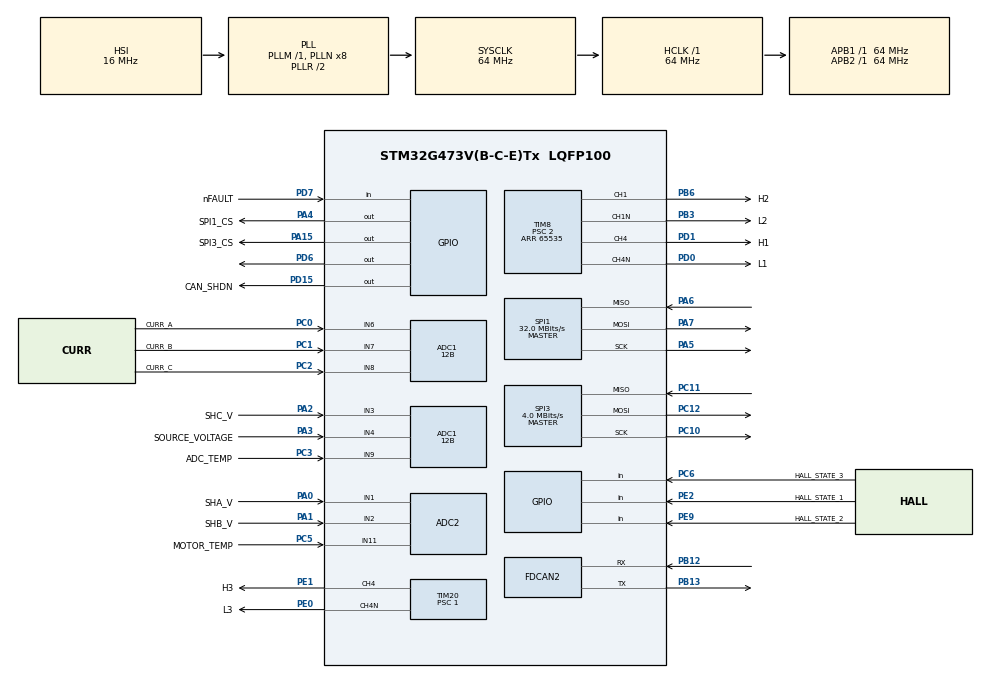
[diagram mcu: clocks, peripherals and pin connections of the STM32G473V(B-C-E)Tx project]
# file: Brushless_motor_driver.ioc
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ADC1.Channel-1\#ChannelRegularConversion=ADC_CHANNEL_6
ADC1.Channel-2\#ChannelRegularConversion=ADC_CHANNEL_7
ADC1.Channel-3\#ChannelRegularConversion=ADC_CHANNEL_8
ADC1.ContinuousConvMode=ENABLE
ADC1.EOCSelection=ADC_EOC_SEQ_CONV
ADC1.NbrOfConversion=3
ADC1.NbrOfConversionFlag=1
ADC1.OffsetNumber-2\#ChannelRegularConversion=ADC_OFFSET_NONE
ADC1.OffsetNumber-3\#ChannelRegularConversion=ADC_OFFSET_NONE
ADC1.Rank-2\#ChannelRegularConversion=2
ADC1.Rank-3\#ChannelRegularConversion=3
ADC1.Resolution=ADC_RESOLUTION_12B
ADC1.SamplingTime-1\#ChannelRegularConversion=ADC_SAMPLETIME_12CYCLES_5
ADC1.SamplingTime-2\#ChannelRegularConversion=ADC_SAMPLETIME_12CYCLES_5
ADC1.SamplingTime-3\#ChannelRegularConversion=ADC_SAMPLETIME_12CYCLES_5
ADC1.master=1
ADC2.Channel-1\#ChannelRegularConversion=ADC_CHANNEL_11
ADC2.NbrOfConversionFlag=1
ADC2.OffsetNumber-1\#ChannelRegularConversion=ADC_OFFSET_NONE
ADC2.Rank-1\#ChannelRegularConversion=1
ADC2.SamplingTime-1\#ChannelRegularConversion=ADC_SAMPLETIME_2CYCLES_5
Dma.ADC1.0.Direction=DMA_PERIPH_TO_MEMORY
Dma.ADC1.0.EventEnable=DISABLE
Dma.ADC1.0.Instance=DMA1_Channel1
Dma.ADC1.0.MemDataAlignment=DMA_MDATAALIGN_WORD
Dma.ADC1.0.MemInc=DMA_MINC_ENABLE
Dma.ADC1.0.Mode=DMA_NORMAL
Dma.ADC1.0.PeriphDataAlignment=DMA_PDATAALIGN_WORD
Dma.ADC1.0.PeriphInc=DMA_PINC_DISABLE
Dma.ADC1.0.Polarity=HAL_DMAMUX_REQ_GEN_RISING
Dma.ADC1.0.Priority=DMA_PRIORITY_MEDIUM
Dma.ADC1.0.RequestNumber=1
Dma.ADC1.0.SignalID=NONE
Dma.ADC1.0.SyncEnable=DISABLE
Dma.ADC1.0.SyncPolarity=HAL_DMAMUX_SYNC_NO_EVENT
Dma.ADC1.0.SyncRequestNumber=1
Dma.ADC1.0.SyncSignalID=NONE
Dma.Request0=ADC1
FDCAN2.CalculateBaudRateNominal=800000
FDCAN2.CalculateTimeBitNominal=1250
FDCAN2.CalculateTimeQuantumNominal=250.0
Mcu.Family=STM32G4
Mcu.Name=STM32G473V(B-C-E)Tx
Mcu.Package=LQFP100
NVIC.CORDIC_IRQn=true\:0\:0\:false\:false\:true\:true\:true\:true
NVIC.DMA1_Channel1_IRQn=true\:0\:0\:false\:false\:true\:false\:true\:true
NVIC.PriorityGroup=NVIC_PRIORITYGROUP_4
NVIC.TIM2_IRQn=true\:0\:0\:false\:false\:true\:true\:true\:true
NVIC.TIM3_IRQn=true\:0\:0\:false\:false\:true\:true\:true\:true
PA0.GPIO_Label=SHA_V
PA0.GPIO_Mode=GPIO_MODE_ANALOG
PA0.GPIO_PuPd=GPIO_NOPULL
PA0.Mode=IN1-Single-Ended
PA0.Signal=ADC2_IN1
PA1.GPIO_Label=SHB_V
PA1.GPIO_Mode=GPIO_MODE_ANALOG
PA1.GPIO_PuPd=GPIO_NOPULL
PA1.Mode=IN2-Single-Ended
PA1.Signal=ADC2_IN2
PA13.Mode=Serial_Wire
PA13.Signal=SYS_JTMS-SWDIO
PA14.Mode=Serial_Wire
PA14.Signal=SYS_JTCK-SWCLK
PA15.GPIO_Label=SPI3_CS
PA15.Signal=GPIO_Output
PA2.GPIO_Label=SHC_V
PA2.GPIO_Mode=GPIO_MODE_ANALOG
PA2.GPIO_PuPd=GPIO_NOPULL
PA2.Mode=IN3-Single-Ended
PA2.Signal=ADC1_IN3
PA3.GPIO_Label=SOURCE_VOLTAGE
PA3.GPIO_Mode=GPIO_MODE_ANALOG
PA3.GPIO_PuPd=GPIO_NOPULL
PA3.Mode=IN4-Single-Ended
PA3.Signal=ADC1_IN4
PA4.GPIO_Label=SPI1_CS
PA4.Signal=GPIO_Output
PA5.Mode=Full_Duplex_Master
PA5.Signal=SPI1_SCK
PA6.Mode=Full_Duplex_Master
PA6.Signal=SPI1_MISO
PA7.Mode=Full_Duplex_Master
PA7.Signal=SPI1_MOSI
PB12.Mode=FDCAN_Activate
PB12.Signal=FDCAN2_RX
PB13.Mode=FDCAN_Activate
PB13.Signal=FDCAN2_TX
PB3.GPIO_Label=L2
PB3.Mode=PWM Generation1 CH1 CH1N
PB3.Signal=TIM8_CH1N
PB6.GPIO_Label=H2
PB6.Signal=S_TIM8_CH1
PC0.GPIO_Label=CURR_A
PC0.GPIO_Mode=GPIO_MODE_ANALOG
PC0.GPIO_PuPd=GPIO_NOPULL
PC0.Mode=IN6-Single-Ended
PC0.Signal=ADC1_IN6
PC1.GPIO_Label=CURR_B
PC1.GPIO_Mode=GPIO_MODE_ANALOG
PC1.GPIO_PuPd=GPIO_NOPULL
PC1.Mode=IN7-Single-Ended
PC1.Signal=ADC1_IN7
PC10.Mode=Full_Duplex_Master
PC10.Signal=SPI3_SCK
PC11.Mode=Full_Duplex_Master
PC11.Signal=SPI3_MISO
PC12.Mode=Full_Duplex_Master
PC12.Signal=SPI3_MOSI
PC2.GPIO_Label=CURR_C
PC2.GPIO_Mode=GPIO_MODE_ANALOG
PC2.GPIO_PuPd=GPIO_NOPULL
PC2.Mode=IN8-Single-Ended
PC2.Signal=ADC1_IN8
PC3.GPIO_Label=ADC_TEMP
PC3.GPIO_Mode=GPIO_MODE_ANALOG
PC3.GPIO_PuPd=GPIO_NOPULL
PC3.Mode=IN9-Single-Ended
PC3.Signal=ADC1_IN9
PC5.GPIO_Label=MOTOR_TEMP
PC5.Mode=IN11-Single-Ended
PC5.Signal=ADC2_IN11
PC6.GPIO_Label=HALL_STATE_3
PC6.Signal=GPIO_Input
PD0.GPIO_Label=L1
PD0.Mode=PWM Generation4 CH4 CH4N
PD0.Signal=TIM8_CH4N
PD1.GPIO_Label=H1
PD1.Signal=S_TIM8_CH4
PD15.GPIO_Label=CAN_SHDN
PD15.Signal=GPIO_Output
PD6.Signal=GPIO_Output
PD7.GPIO_Label=nFAULT
PD7.Signal=GPIO_Input
PE0.GPIO_Label=L3
PE0.Mode=PWM Generation4 CH4 CH4N
PE0.Signal=TIM20_CH4N
PE1.GPIO_Label=H3
PE1.Signal=S_TIM20_CH4
PE2.GPIO_Label=HALL_STATE_1
PE2.Signal=GPIO_Input
PE9.GPIO_Label=HALL_STATE_2
PE9.Signal=GPIO_Input
ProjectManager.HeapSize=0x200
ProjectManager.StackSize=0x400
ProjectManager.TargetToolchain=STM32CubeIDE
RCC.ADC12Freq_Value=64000000
RCC.ADC345Freq_Value=64000000
RCC.AHBFreq_Value=64000000
RCC.APB1Freq_Value=64000000
RCC.APB1TimFreq_Value=64000000
RCC.APB2Freq_Value=64000000
RCC.APB2TimFreq_Value=64000000
RCC.CortexFreq_Value=64000000
RCC.EXTERNAL_CLOCK_VALUE=12288000
RCC.HCLKFreq_Value=64000000
RCC.HSE_VALUE=8000000
RCC.HSI48_VALUE=48000000
RCC.HSI_VALUE=16000000
RCC.LSE_VALUE=32768
RCC.SYSCLKFreq_VALUE=64000000
RCC.SYSCLKSource=RCC_SYSCLKSOURCE_PLLCLK
RCC.USBFreq_Value=64000000
RCC.VCOOutputFreq_Value=128000000
SH.S_TIM20_CH4.0=TIM20_CH4,PWM Generation4 CH4 CH4N
SH.S_TIM8_CH1.0=TIM8_CH1,PWM Generation1 CH1 CH1N
SH.S_TIM8_CH4.0=TIM8_CH4,PWM Generation4 CH4 CH4N
SPI1.BaudRatePrescaler=SPI_BAUDRATEPRESCALER_2
SPI1.CalculateBaudRate=32.0 MBits/s
SPI1.Direction=SPI_DIRECTION_2LINES
SPI1.Mode=SPI_MODE_MASTER
SPI1.VirtualType=VM_MASTER
SPI3.BaudRatePrescaler=SPI_BAUDRATEPRESCALER_16
SPI3.CalculateBaudRate=4.0 MBits/s
SPI3.Direction=SPI_DIRECTION_2LINES
SPI3.Mode=SPI_MODE_MASTER
SPI3.VirtualType=VM_MASTER
TIM2.Channel-Output\ Compare1\ No\ Output=TIM_CHANNEL_1
TIM2.PeriodNoDither=71582788
TIM20.Channel-PWM\ Generation4\ CH4\ CH4N=TIM_CHANNEL_4
TIM20.CounterMode=TIM_COUNTERMODE_CENTERALIGNED2
TIM20.OCMode_PWM-PWM\ Generation4\ CH4\ CH4N=TIM_OCMODE_PWM1
TIM20.PeriodNoDither=65535
TIM20.Prescaler=1
TIM8.AutoReloadPreload=TIM_AUTORELOAD_PRELOAD_ENABLE
TIM8.Channel-PWM\ Generation1\ CH1\ CH1N=TIM_CHANNEL_1
TIM8.Channel-PWM\ Generation4\ CH4\ CH4N=TIM_CHANNEL_4
TIM8.CounterMode=TIM_COUNTERMODE_CENTERALIGNED2
TIM8.OCMode_PWM-PWM\ Generation4\ CH4\ CH4N=TIM_OCMODE_PWM1
TIM8.PeriodNoDither=65535
TIM8.Prescaler=2
VP_CORDIC_VS_CORDIC.Mode=CORDIC_Activate
VP_SYS_VS_DBSignals.Mode=DisableDeadBatterySignals
VP_TIM1_VS_ClockSourceINT.Mode=Internal
VP_TIM20_VS_ClockSourceINT.Mode=Internal
VP_TIM2_VS_ClockSourceINT.Mode=Internal
VP_TIM2_VS_no_output1.Mode=Output Compare1 No Output
VP_TIM3_VS_ClockSourceINT.Mode=Internal
VP_TIM8_VS_ClockSourceINT.Mode=Internal
board=custom

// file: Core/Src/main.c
/* USER CODE BEGIN Header */
/**
  ******************************************************************************
  * @file           : main.c
  * @brief          : Main program body
  ******************************************************************************
  * @attention
  *
  * Copyright (c) 2023 STMicroelectronics.
  * All rights reserved.
  *
  * This software is licensed under terms that can be found in the LICENSE file
  * in the root directory of this software component.
  * If no LICENSE file comes with this software, it is provided AS-IS.
  *
  ******************************************************************************
  */
/* USER CODE END Header */
#include "main.h"

/* USER CODE BEGIN Includes */
#include "main_bridge.h"
/* USER CODE END Includes */

ADC_HandleTypeDef hadc1;
ADC_HandleTypeDef hadc2;
DMA_HandleTypeDef hdma_adc1;

CORDIC_HandleTypeDef hcordic;

FDCAN_HandleTypeDef hfdcan2;

SPI_HandleTypeDef hspi1;
SPI_HandleTypeDef hspi3;

TIM_HandleTypeDef htim1;
TIM_HandleTypeDef htim2;
TIM_HandleTypeDef htim3;
TIM_HandleTypeDef htim8;
TIM_HandleTypeDef htim20;

void SystemClock_Config(void);
static void MX_GPIO_Init(void);
static void MX_DMA_Init(void);
static void MX_ADC1_Init(void);
static void MX_TIM3_Init(void);
static void MX_ADC2_Init(void);
static void MX_TIM2_Init(void);
static void MX_TIM1_Init(void);
static void MX_TIM8_Init(void);
static void MX_TIM20_Init(void);
static void MX_FDCAN2_Init(void);
static void MX_SPI1_Init(void);
static void MX_SPI3_Init(void);
static void MX_CORDIC_Init(void);

int main(void)
{
  /* USER CODE BEGIN 1 */
	TIM2->CCR1 = 17895697;
  /* USER CODE END 1 */

  /* MCU Configuration--------------------------------------------------------*/

  /* Reset of all peripherals, Initializes the Flash interface and the Systick. */
  HAL_Init();

  /* Configure the system clock */
  SystemClock_Config();

  /* Initialize all configured peripherals */
  MX_GPIO_Init();
  MX_DMA_Init();
  MX_ADC1_Init();
  MX_TIM3_Init();
  MX_ADC2_Init();
  MX_TIM2_Init();
  MX_TIM1_Init();
  MX_TIM8_Init();
  MX_TIM20_Init();
  MX_FDCAN2_Init();
  MX_SPI1_Init();
  MX_SPI3_Init();
  MX_CORDIC_Init();
  /* USER CODE BEGIN 2 */
  setup();
  /* USER CODE END 2 */

  /* Infinite loop */
  /* USER CODE BEGIN WHILE */
  while (1)
  {
	  loop();
    /* USER CODE END WHILE */

  }
}

void SystemClock_Config(void)
{
  RCC_OscInitTypeDef RCC_OscInitStruct = {0};
  RCC_ClkInitTypeDef RCC_ClkInitStruct = {0};

  /** Configure the main internal regulator output voltage
  */
  HAL_PWREx_ControlVoltageScaling(PWR_REGULATOR_VOLTAGE_SCALE1);

  /** Initializes the RCC Oscillators according to the specified parameters
  * in the RCC_OscInitTypeDef structure.
  */
  RCC_OscInitStruct.OscillatorType = RCC_OSCILLATORTYPE_HSI;
  RCC_OscInitStruct.HSIState = RCC_HSI_ON;
  RCC_OscInitStruct.HSICalibrationValue = RCC_HSICALIBRATION_DEFAULT;
  RCC_OscInitStruct.PLL.PLLState = RCC_PLL_ON;
  RCC_OscInitStruct.PLL.PLLSource = RCC_PLLSOURCE_HSI;
  RCC_OscInitStruct.PLL.PLLM = RCC_PLLM_DIV1;
  RCC_OscInitStruct.PLL.PLLN = 8;
  RCC_OscInitStruct.PLL.PLLP = RCC_PLLP_DIV2;
  RCC_OscInitStruct.PLL.PLLQ = RCC_PLLQ_DIV2;
  RCC_OscInitStruct.PLL.PLLR = RCC_PLLR_DIV2;
  if (HAL_RCC_OscConfig(&RCC_OscInitStruct) != HAL_OK)
  {
    Error_Handler();
  }

  /** Initializes the CPU, AHB and APB buses clocks
  */
  RCC_ClkInitStruct.ClockType = RCC_CLOCKTYPE_HCLK|RCC_CLOCKTYPE_SYSCLK
                              |RCC_CLOCKTYPE_PCLK1|RCC_CLOCKTYPE_PCLK2;
  RCC_ClkInitStruct.SYSCLKSource = RCC_SYSCLKSOURCE_PLLCLK;
  RCC_ClkInitStruct.AHBCLKDivider = RCC_SYSCLK_DIV1;
  RCC_ClkInitStruct.APB1CLKDivider = RCC_HCLK_DIV1;
  RCC_ClkInitStruct.APB2CLKDivider = RCC_HCLK_DIV1;

  if (HAL_RCC_ClockConfig(&RCC_ClkInitStruct, FLASH_LATENCY_2) != HAL_OK)
  {
    Error_Handler();
  }
}

static void MX_ADC1_Init(void)
{

  ADC_MultiModeTypeDef multimode = {0};
  ADC_ChannelConfTypeDef sConfig = {0};

  /** Common config
  */
  hadc1.Instance = ADC1;
  hadc1.Init.ClockPrescaler = ADC_CLOCK_SYNC_PCLK_DIV2;
  hadc1.Init.Resolution = ADC_RESOLUTION_12B;
  hadc1.Init.DataAlign = ADC_DATAALIGN_RIGHT;
  hadc1.Init.GainCompensation = 0;
  hadc1.Init.ScanConvMode = ADC_SCAN_ENABLE;
  hadc1.Init.EOCSelection = ADC_EOC_SEQ_CONV;
  hadc1.Init.LowPowerAutoWait = DISABLE;
  hadc1.Init.ContinuousConvMode = ENABLE;
  hadc1.Init.NbrOfConversion = 3;
  hadc1.Init.DiscontinuousConvMode = DISABLE;
  hadc1.Init.ExternalTrigConv = ADC_SOFTWARE_START;
  hadc1.Init.ExternalTrigConvEdge = ADC_EXTERNALTRIGCONVEDGE_NONE;
  hadc1.Init.DMAContinuousRequests = DISABLE;
  hadc1.Init.Overrun = ADC_OVR_DATA_PRESERVED;
  hadc1.Init.OversamplingMode = DISABLE;
  if (HAL_ADC_Init(&hadc1) != HAL_OK)
  {
    Error_Handler();
  }

  /** Configure the ADC multi-mode
  */
  multimode.Mode = ADC_MODE_INDEPENDENT;
  if (HAL_ADCEx_MultiModeConfigChannel(&hadc1, &multimode) != HAL_OK)
  {
    Error_Handler();
  }

  /** Configure Regular Channel
  */
  sConfig.Channel = ADC_CHANNEL_6;
  sConfig.Rank = ADC_REGULAR_RANK_1;
  sConfig.SamplingTime = ADC_SAMPLETIME_12CYCLES_5;
  sConfig.SingleDiff = ADC_SINGLE_ENDED;
  sConfig.OffsetNumber = ADC_OFFSET_NONE;
  sConfig.Offset = 0;
  if (HAL_ADC_ConfigChannel(&hadc1, &sConfig) != HAL_OK)
  {
    Error_Handler();
  }

  /** Configure Regular Channel
  */
  sConfig.Channel = ADC_CHANNEL_7;
  sConfig.Rank = ADC_REGULAR_RANK_2;
  if (HAL_ADC_ConfigChannel(&hadc1, &sConfig) != HAL_OK)
  {
    Error_Handler();
  }

  /** Configure Regular Channel
  */
  sConfig.Channel = ADC_CHANNEL_8;
  sConfig.Rank = ADC_REGULAR_RANK_3;
  if (HAL_ADC_ConfigChannel(&hadc1, &sConfig) != HAL_OK)
  {
    Error_Handler();
  }

}

static void MX_ADC2_Init(void)
{

  ADC_ChannelConfTypeDef sConfig = {0};

  /** Common config
  */
  hadc2.Instance = ADC2;
  hadc2.Init.ClockPrescaler = ADC_CLOCK_SYNC_PCLK_DIV2;
  hadc2.Init.Resolution = ADC_RESOLUTION_12B;
  hadc2.Init.DataAlign = ADC_DATAALIGN_RIGHT;
  hadc2.Init.GainCompensation = 0;
  hadc2.Init.ScanConvMode = ADC_SCAN_DISABLE;
  hadc2.Init.EOCSelection = ADC_EOC_SINGLE_CONV;
  hadc2.Init.LowPowerAutoWait = DISABLE;
  hadc2.Init.ContinuousConvMode = DISABLE;
  hadc2.Init.NbrOfConversion = 1;
  hadc2.Init.DiscontinuousConvMode = DISABLE;
  hadc2.Init.ExternalTrigConv = ADC_SOFTWARE_START;
  hadc2.Init.ExternalTrigConvEdge = ADC_EXTERNALTRIGCONVEDGE_NONE;
  hadc2.Init.DMAContinuousRequests = DISABLE;
  hadc2.Init.Overrun = ADC_OVR_DATA_PRESERVED;
  hadc2.Init.OversamplingMode = DISABLE;
  if (HAL_ADC_Init(&hadc2) != HAL_OK)
  {
    Error_Handler();
  }

  /** Configure Regular Channel
  */
  sConfig.Channel = ADC_CHANNEL_11;
  sConfig.Rank = ADC_REGULAR_RANK_1;
  sConfig.SamplingTime = ADC_SAMPLETIME_2CYCLES_5;
  sConfig.SingleDiff = ADC_SINGLE_ENDED;
  sConfig.OffsetNumber = ADC_OFFSET_NONE;
  sConfig.Offset = 0;
  if (HAL_ADC_ConfigChannel(&hadc2, &sConfig) != HAL_OK)
  {
    Error_Handler();
  }

}

static void MX_CORDIC_Init(void)
{

  hcordic.Instance = CORDIC;
  if (HAL_CORDIC_Init(&hcordic) != HAL_OK)
  {
    Error_Handler();
  }

}

static void MX_FDCAN2_Init(void)
{

  hfdcan2.Instance = FDCAN2;
  hfdcan2.Init.ClockDivider = FDCAN_CLOCK_DIV1;
  hfdcan2.Init.FrameFormat = FDCAN_FRAME_CLASSIC;
  hfdcan2.Init.Mode = FDCAN_MODE_NORMAL;
  hfdcan2.Init.AutoRetransmission = DISABLE;
  hfdcan2.Init.TransmitPause = DISABLE;
  hfdcan2.Init.ProtocolException = DISABLE;
  hfdcan2.Init.NominalPrescaler = 16;
  hfdcan2.Init.NominalSyncJumpWidth = 1;
  hfdcan2.Init.NominalTimeSeg1 = 2;
  hfdcan2.Init.NominalTimeSeg2 = 2;
  hfdcan2.Init.DataPrescaler = 1;
  hfdcan2.Init.DataSyncJumpWidth = 1;
  hfdcan2.Init.DataTimeSeg1 = 1;
  hfdcan2.Init.DataTimeSeg2 = 1;
  hfdcan2.Init.StdFiltersNbr = 0;
  hfdcan2.Init.ExtFiltersNbr = 0;
  hfdcan2.Init.TxFifoQueueMode = FDCAN_TX_FIFO_OPERATION;
  if (HAL_FDCAN_Init(&hfdcan2) != HAL_OK)
  {
    Error_Handler();
  }

}

static void MX_SPI1_Init(void)
{

  /* SPI1 parameter configuration*/
  hspi1.Instance = SPI1;
  hspi1.Init.Mode = SPI_MODE_MASTER;
  hspi1.Init.Direction = SPI_DIRECTION_2LINES;
  hspi1.Init.DataSize = SPI_DATASIZE_4BIT;
  hspi1.Init.CLKPolarity = SPI_POLARITY_LOW;
  hspi1.Init.CLKPhase = SPI_PHASE_1EDGE;
  hspi1.Init.NSS = SPI_NSS_SOFT;
  hspi1.Init.BaudRatePrescaler = SPI_BAUDRATEPRESCALER_2;
  hspi1.Init.FirstBit = SPI_FIRSTBIT_MSB;
  hspi1.Init.TIMode = SPI_TIMODE_DISABLE;
  hspi1.Init.CRCCalculation = SPI_CRCCALCULATION_DISABLE;
  hspi1.Init.CRCPolynomial = 7;
  hspi1.Init.CRCLength = SPI_CRC_LENGTH_DATASIZE;
  hspi1.Init.NSSPMode = SPI_NSS_PULSE_ENABLE;
  if (HAL_SPI_Init(&hspi1) != HAL_OK)
  {
    Error_Handler();
  }

}

static void MX_SPI3_Init(void)
{

  /* SPI3 parameter configuration*/
  hspi3.Instance = SPI3;
  hspi3.Init.Mode = SPI_MODE_MASTER;
  hspi3.Init.Direction = SPI_DIRECTION_2LINES;
  hspi3.Init.DataSize = SPI_DATASIZE_4BIT;
  hspi3.Init.CLKPolarity = SPI_POLARITY_LOW;
  hspi3.Init.CLKPhase = SPI_PHASE_1EDGE;
  hspi3.Init.NSS = SPI_NSS_SOFT;
  hspi3.Init.BaudRatePrescaler = SPI_BAUDRATEPRESCALER_16;
  hspi3.Init.FirstBit = SPI_FIRSTBIT_MSB;
  hspi3.Init.TIMode = SPI_TIMODE_DISABLE;
  hspi3.Init.CRCCalculation = SPI_CRCCALCULATION_DISABLE;
  hspi3.Init.CRCPolynomial = 7;
  hspi3.Init.CRCLength = SPI_CRC_LENGTH_DATASIZE;
  hspi3.Init.NSSPMode = SPI_NSS_PULSE_ENABLE;
  if (HAL_SPI_Init(&hspi3) != HAL_OK)
  {
    Error_Handler();
  }

}

static void MX_TIM1_Init(void)
{

  TIM_ClockConfigTypeDef sClockSourceConfig = {0};
  TIM_MasterConfigTypeDef sMasterConfig = {0};

  htim1.Instance = TIM1;
  htim1.Init.Prescaler = 0;
  htim1.Init.CounterMode = TIM_COUNTERMODE_UP;
  htim1.Init.Period = 65535;
  htim1.Init.ClockDivision = TIM_CLOCKDIVISION_DIV1;
  htim1.Init.RepetitionCounter = 0;
  htim1.Init.AutoReloadPreload = TIM_AUTORELOAD_PRELOAD_DISABLE;
  if (HAL_TIM_Base_Init(&htim1) != HAL_OK)
  {
    Error_Handler();
  }
  sClockSourceConfig.ClockSource = TIM_CLOCKSOURCE_INTERNAL;
  if (HAL_TIM_ConfigClockSource(&htim1, &sClockSourceConfig) != HAL_OK)
  {
    Error_Handler();
  }
  sMasterConfig.MasterOutputTrigger = TIM_TRGO_RESET;
  sMasterConfig.MasterOutputTrigger2 = TIM_TRGO2_RESET;
  sMasterConfig.MasterSlaveMode = TIM_MASTERSLAVEMODE_DISABLE;
  if (HAL_TIMEx_MasterConfigSynchronization(&htim1, &sMasterConfig) != HAL_OK)
  {
    Error_Handler();
  }

}

static void MX_TIM2_Init(void)
{

  TIM_ClockConfigTypeDef sClockSourceConfig = {0};
  TIM_MasterConfigTypeDef sMasterConfig = {0};
  TIM_OC_InitTypeDef sConfigOC = {0};

  htim2.Instance = TIM2;
  htim2.Init.Prescaler = 0;
  htim2.Init.CounterMode = TIM_COUNTERMODE_UP;
  htim2.Init.Period = 7.1582788E7;
  htim2.Init.ClockDivision = TIM_CLOCKDIVISION_DIV1;
  htim2.Init.AutoReloadPreload = TIM_AUTORELOAD_PRELOAD_DISABLE;
  if (HAL_TIM_Base_Init(&htim2) != HAL_OK)
  {
    Error_Handler();
  }
  sClockSourceConfig.ClockSource = TIM_CLOCKSOURCE_INTERNAL;
  if (HAL_TIM_ConfigClockSource(&htim2, &sClockSourceConfig) != HAL_OK)
  {
    Error_Handler();
  }
  if (HAL_TIM_OC_Init(&htim2) != HAL_OK)
  {
    Error_Handler();
  }
  sMasterConfig.MasterOutputTrigger = TIM_TRGO_RESET;
  sMasterConfig.MasterSlaveMode = TIM_MASTERSLAVEMODE_DISABLE;
  if (HAL_TIMEx_MasterConfigSynchronization(&htim2, &sMasterConfig) != HAL_OK)
  {
    Error_Handler();
  }
  sConfigOC.OCMode = TIM_OCMODE_TIMING;
  sConfigOC.Pulse = 0;
  sConfigOC.OCPolarity = TIM_OCPOLARITY_HIGH;
  sConfigOC.OCFastMode = TIM_OCFAST_DISABLE;
  if (HAL_TIM_OC_ConfigChannel(&htim2, &sConfigOC, TIM_CHANNEL_1) != HAL_OK)
  {
    Error_Handler();
  }

}

static void MX_TIM3_Init(void)
{

  TIM_ClockConfigTypeDef sClockSourceConfig = {0};
  TIM_MasterConfigTypeDef sMasterConfig = {0};

  htim3.Instance = TIM3;
  htim3.Init.Prescaler = 0;
  htim3.Init.CounterMode = TIM_COUNTERMODE_UP;
  htim3.Init.Period = 65535;
  htim3.Init.ClockDivision = TIM_CLOCKDIVISION_DIV1;
  htim3.Init.AutoReloadPreload = TIM_AUTORELOAD_PRELOAD_DISABLE;
  if (HAL_TIM_Base_Init(&htim3) != HAL_OK)
  {
    Error_Handler();
  }
  sClockSourceConfig.ClockSource = TIM_CLOCKSOURCE_INTERNAL;
  if (HAL_TIM_ConfigClockSource(&htim3, &sClockSourceConfig) != HAL_OK)
  {
    Error_Handler();
  }
  sMasterConfig.MasterOutputTrigger = TIM_TRGO_RESET;
  sMasterConfig.MasterSlaveMode = TIM_MASTERSLAVEMODE_DISABLE;
  if (HAL_TIMEx_MasterConfigSynchronization(&htim3, &sMasterConfig) != HAL_OK)
  {
    Error_Handler();
  }

}

static void MX_TIM8_Init(void)
{

  TIM_ClockConfigTypeDef sClockSourceConfig = {0};
  TIM_MasterConfigTypeDef sMasterConfig = {0};
  TIM_OC_InitTypeDef sConfigOC = {0};
  TIM_BreakDeadTimeConfigTypeDef sBreakDeadTimeConfig = {0};

  htim8.Instance = TIM8;
  htim8.Init.Prescaler = 2;
  htim8.Init.CounterMode = TIM_COUNTERMODE_CENTERALIGNED2;
  htim8.Init.Period = 65535;
  htim8.Init.ClockDivision = TIM_CLOCKDIVISION_DIV1;
  htim8.Init.RepetitionCounter = 0;
  htim8.Init.AutoReloadPreload = TIM_AUTORELOAD_PRELOAD_ENABLE;
  if (HAL_TIM_Base_Init(&htim8) != HAL_OK)
  {
    Error_Handler();
  }
  sClockSourceConfig.ClockSource = TIM_CLOCKSOURCE_INTERNAL;
  if (HAL_TIM_ConfigClockSource(&htim8, &sClockSourceConfig) != HAL_OK)
  {
    Error_Handler();
  }
  if (HAL_TIM_PWM_Init(&htim8) != HAL_OK)
  {
    Error_Handler();
  }
  sMasterConfig.MasterOutputTrigger = TIM_TRGO_RESET;
  sMasterConfig.MasterOutputTrigger2 = TIM_TRGO2_RESET;
  sMasterConfig.MasterSlaveMode = TIM_MASTERSLAVEMODE_DISABLE;
  if (HAL_TIMEx_MasterConfigSynchronization(&htim8, &sMasterConfig) != HAL_OK)
  {
    Error_Handler();
  }
  sConfigOC.OCMode = TIM_OCMODE_PWM1;
  sConfigOC.Pulse = 0;
  sConfigOC.OCPolarity = TIM_OCPOLARITY_HIGH;
  sConfigOC.OCNPolarity = TIM_OCNPOLARITY_HIGH;
  sConfigOC.OCFastMode = TIM_OCFAST_DISABLE;
  sConfigOC.OCIdleState = TIM_OCIDLESTATE_RESET;
  sConfigOC.OCNIdleState = TIM_OCNIDLESTATE_RESET;
  if (HAL_TIM_PWM_ConfigChannel(&htim8, &sConfigOC, TIM_CHANNEL_1) != HAL_OK)
  {
    Error_Handler();
  }
  if (HAL_TIM_PWM_ConfigChannel(&htim8, &sConfigOC, TIM_CHANNEL_4) != HAL_OK)
  {
    Error_Handler();
  }
  sBreakDeadTimeConfig.OffStateRunMode = TIM_OSSR_DISABLE;
  sBreakDeadTimeConfig.OffStateIDLEMode = TIM_OSSI_DISABLE;
  sBreakDeadTimeConfig.LockLevel = TIM_LOCKLEVEL_OFF;
  sBreakDeadTimeConfig.DeadTime = 0;
  sBreakDeadTimeConfig.BreakState = TIM_BREAK_DISABLE;
  sBreakDeadTimeConfig.BreakPolarity = TIM_BREAKPOLARITY_HIGH;
  sBreakDeadTimeConfig.BreakFilter = 0;
  sBreakDeadTimeConfig.BreakAFMode = TIM_BREAK_AFMODE_INPUT;
  sBreakDeadTimeConfig.Break2State = TIM_BREAK2_DISABLE;
  sBreakDeadTimeConfig.Break2Polarity = TIM_BREAK2POLARITY_HIGH;
  sBreakDeadTimeConfig.Break2Filter = 0;
  sBreakDeadTimeConfig.Break2AFMode = TIM_BREAK_AFMODE_INPUT;
  sBreakDeadTimeConfig.AutomaticOutput = TIM_AUTOMATICOUTPUT_DISABLE;
  if (HAL_TIMEx_ConfigBreakDeadTime(&htim8, &sBreakDeadTimeConfig) != HAL_OK)
  {
    Error_Handler();
  }
  HAL_TIM_MspPostInit(&htim8);

}

static void MX_TIM20_Init(void)
{

  TIM_ClockConfigTypeDef sClockSourceConfig = {0};
  TIM_MasterConfigTypeDef sMasterConfig = {0};
  TIM_OC_InitTypeDef sConfigOC = {0};
  TIM_BreakDeadTimeConfigTypeDef sBreakDeadTimeConfig = {0};

  htim20.Instance = TIM20;
  htim20.Init.Prescaler = 1;
  htim20.Init.CounterMode = TIM_COUNTERMODE_CENTERALIGNED2;
  htim20.Init.Period = 65535;
  htim20.Init.ClockDivision = TIM_CLOCKDIVISION_DIV1;
  htim20.Init.RepetitionCounter = 0;
  htim20.Init.AutoReloadPreload = TIM_AUTORELOAD_PRELOAD_DISABLE;
  if (HAL_TIM_Base_Init(&htim20) != HAL_OK)
  {
    Error_Handler();
  }
  sClockSourceConfig.ClockSource = TIM_CLOCKSOURCE_INTERNAL;
  if (HAL_TIM_ConfigClockSource(&htim20, &sClockSourceConfig) != HAL_OK)
  {
    Error_Handler();
  }
  if (HAL_TIM_PWM_Init(&htim20) != HAL_OK)
  {
    Error_Handler();
  }
  sMasterConfig.MasterOutputTrigger = TIM_TRGO_RESET;
  sMasterConfig.MasterOutputTrigger2 = TIM_TRGO2_RESET;
  sMasterConfig.MasterSlaveMode = TIM_MASTERSLAVEMODE_DISABLE;
  if (HAL_TIMEx_MasterConfigSynchronization(&htim20, &sMasterConfig) != HAL_OK)
  {
    Error_Handler();
  }
  sConfigOC.OCMode = TIM_OCMODE_PWM1;
  sConfigOC.Pulse = 0;
  sConfigOC.OCPolarity = TIM_OCPOLARITY_HIGH;
  sConfigOC.OCNPolarity = TIM_OCNPOLARITY_HIGH;
  sConfigOC.OCFastMode = TIM_OCFAST_DISABLE;
  sConfigOC.OCIdleState = TIM_OCIDLESTATE_RESET;
  sConfigOC.OCNIdleState = TIM_OCNIDLESTATE_RESET;
  if (HAL_TIM_PWM_ConfigChannel(&htim20, &sConfigOC, TIM_CHANNEL_4) != HAL_OK)
  {
    Error_Handler();
  }
  sBreakDeadTimeConfig.OffStateRunMode = TIM_OSSR_DISABLE;
  sBreakDeadTimeConfig.OffStateIDLEMode = TIM_OSSI_DISABLE;
  sBreakDeadTimeConfig.LockLevel = TIM_LOCKLEVEL_OFF;
  sBreakDeadTimeConfig.DeadTime = 0;
  sBreakDeadTimeConfig.BreakState = TIM_BREAK_DISABLE;
  sBreakDeadTimeConfig.BreakPolarity = TIM_BREAKPOLARITY_HIGH;
  sBreakDeadTimeConfig.BreakFilter = 0;
  sBreakDeadTimeConfig.BreakAFMode = TIM_BREAK_AFMODE_INPUT;
  sBreakDeadTimeConfig.Break2State = TIM_BREAK2_DISABLE;
  sBreakDeadTimeConfig.Break2Polarity = TIM_BREAK2POLARITY_HIGH;
  sBreakDeadTimeConfig.Break2Filter = 0;
  sBreakDeadTimeConfig.Break2AFMode = TIM_BREAK_AFMODE_INPUT;
  sBreakDeadTimeConfig.AutomaticOutput = TIM_AUTOMATICOUTPUT_DISABLE;
  if (HAL_TIMEx_ConfigBreakDeadTime(&htim20, &sBreakDeadTimeConfig) != HAL_OK)
  {
    Error_Handler();
  }
  HAL_TIM_MspPostInit(&htim20);

}

static void MX_DMA_Init(void)
{

  /* DMA controller clock enable */
  __HAL_RCC_DMAMUX1_CLK_ENABLE();
  __HAL_RCC_DMA1_CLK_ENABLE();

  /* DMA interrupt init */
  /* DMA1_Channel1_IRQn interrupt configuration */
  HAL_NVIC_SetPriority(DMA1_Channel1_IRQn, 0, 0);
  HAL_NVIC_EnableIRQ(DMA1_Channel1_IRQn);

}

static void MX_GPIO_Init(void)
{
  GPIO_InitTypeDef GPIO_InitStruct = {0};

  /* GPIO Ports Clock Enable */
  __HAL_RCC_GPIOE_CLK_ENABLE();
  __HAL_RCC_GPIOC_CLK_ENABLE();
  __HAL_RCC_GPIOA_CLK_ENABLE();
  __HAL_RCC_GPIOB_CLK_ENABLE();
  __HAL_RCC_GPIOD_CLK_ENABLE();

  /*Configure GPIO pin Output Level */
  HAL_GPIO_WritePin(GPIOA, SPI1_CS_Pin|SPI3_CS_Pin, GPIO_PIN_RESET);

  /*Configure GPIO pin Output Level */
  HAL_GPIO_WritePin(GPIOD, CAN_SHDN_Pin|GPIO_PIN_6, GPIO_PIN_RESET);

  /*Configure GPIO pins : HALL_STATE_1_Pin HALL_STATE_2_Pin */
  GPIO_InitStruct.Pin = HALL_STATE_1_Pin|HALL_STATE_2_Pin;
  GPIO_InitStruct.Mode = GPIO_MODE_INPUT;
  GPIO_InitStruct.Pull = GPIO_NOPULL;
  HAL_GPIO_Init(GPIOE, &GPIO_InitStruct);

  /*Configure GPIO pins : SPI1_CS_Pin SPI3_CS_Pin */
  GPIO_InitStruct.Pin = SPI1_CS_Pin|SPI3_CS_Pin;
  GPIO_InitStruct.Mode = GPIO_MODE_OUTPUT_PP;
  GPIO_InitStruct.Pull = GPIO_NOPULL;
  GPIO_InitStruct.Speed = GPIO_SPEED_FREQ_LOW;
  HAL_GPIO_Init(GPIOA, &GPIO_InitStruct);

  /*Configure GPIO pins : CAN_SHDN_Pin PD6 */
  GPIO_InitStruct.Pin = CAN_SHDN_Pin|GPIO_PIN_6;
  GPIO_InitStruct.Mode = GPIO_MODE_OUTPUT_PP;
  GPIO_InitStruct.Pull = GPIO_NOPULL;
  GPIO_InitStruct.Speed = GPIO_SPEED_FREQ_LOW;
  HAL_GPIO_Init(GPIOD, &GPIO_InitStruct);

  /*Configure GPIO pin : HALL_STATE_3_Pin */
  GPIO_InitStruct.Pin = HALL_STATE_3_Pin;
  GPIO_InitStruct.Mode = GPIO_MODE_INPUT;
  GPIO_InitStruct.Pull = GPIO_NOPULL;
  HAL_GPIO_Init(HALL_STATE_3_GPIO_Port, &GPIO_InitStruct);

  /*Configure GPIO pin : nFAULT_Pin */
  GPIO_InitStruct.Pin = nFAULT_Pin;
  GPIO_InitStruct.Mode = GPIO_MODE_INPUT;
  GPIO_InitStruct.Pull = GPIO_NOPULL;
  HAL_GPIO_Init(nFAULT_GPIO_Port, &GPIO_InitStruct);

}

void Error_Handler(void)
{
  __disable_irq();
  while (1)
  {
  }
}
